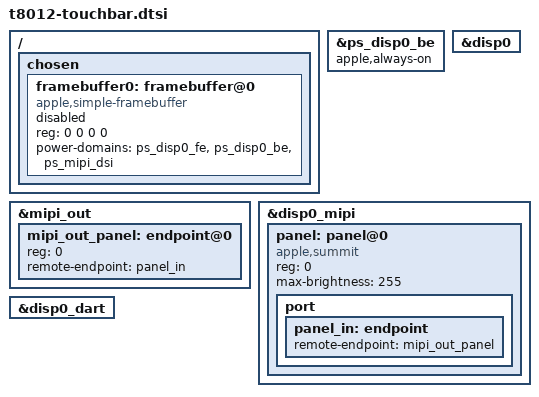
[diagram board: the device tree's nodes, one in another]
// SPDX-License-Identifier: GPL-2.0+ OR MIT
/*
 * Common Device Tree for T2 devices with a Touch Bar
 *
 * target-type: J152f, J213, J214k, J215, J223, J680, J780
 *
 * Copyright (c) 2024, Nick Chan <towinchenmi@gmail.com>
 */

/ {
	chosen {
		framebuffer0: framebuffer@0 {
			compatible = "apple,simple-framebuffer", "simple-framebuffer";
			reg = <0 0 0 0>; /* To be filled by loader */
			power-domains = <&ps_disp0_fe &ps_disp0_be &ps_mipi_dsi>;
			/* Format properties will be added by loader */
			status = "disabled";
		};
	};
};

/*
 * The driver depends on boot loader initialized state which resets when this
 * power-domain is powered off. This happens on suspend or when the driver is
 * missing during boot. Mark the domain as always on until the driver can
 * handle this.
 */
&ps_disp0_be {
	apple,always-on;
};

&disp0 {
	status = "okay";
};

&mipi_out {
	mipi_out_panel: endpoint@0 {
		reg = <0>;
		remote-endpoint = <&panel_in>;
	};
};

&disp0_mipi {
	status = "okay";
	#address-cells = <1>;
	#size-cells = <0>;

	panel: panel@0 {
		compatible = "apple,summit";
		reg = <0>;
		max-brightness = <255>;

		port {
			panel_in: endpoint {
				remote-endpoint = <&mipi_out_panel>;
			};
		};
	};
};

&disp0_dart {
	status = "okay";
};
